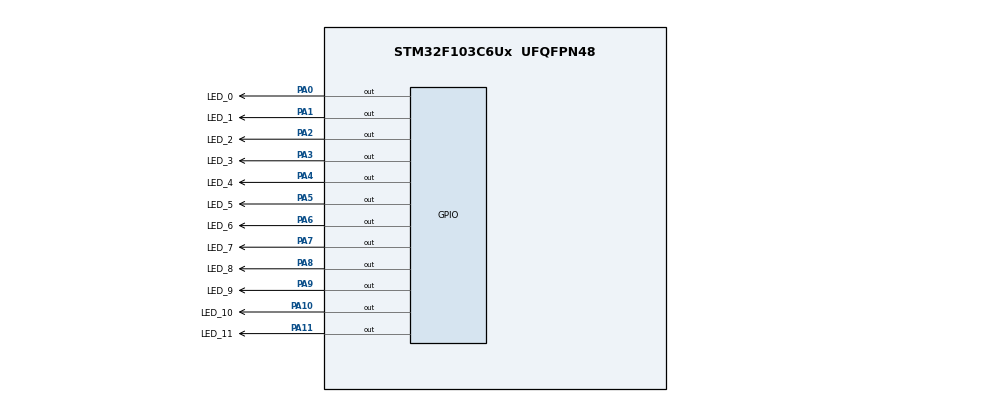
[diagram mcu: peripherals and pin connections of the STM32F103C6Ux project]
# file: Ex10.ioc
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Mcu.Family=STM32F1
Mcu.Name=STM32F103C6Ux
Mcu.Package=UFQFPN48
NVIC.PriorityGroup=NVIC_PRIORITYGROUP_4
PA0-WKUP.GPIO_Label=LED_0
PA0-WKUP.Signal=GPIO_Output
PA1.GPIO_Label=LED_1
PA1.Signal=GPIO_Output
PA10.GPIO_Label=LED_10
PA10.Signal=GPIO_Output
PA11.GPIO_Label=LED_11
PA11.Signal=GPIO_Output
PA2.GPIO_Label=LED_2
PA2.Signal=GPIO_Output
PA3.GPIO_Label=LED_3
PA3.Signal=GPIO_Output
PA4.GPIO_Label=LED_4
PA4.Signal=GPIO_Output
PA5.GPIO_Label=LED_5
PA5.Signal=GPIO_Output
PA6.GPIO_Label=LED_6
PA6.Signal=GPIO_Output
PA7.GPIO_Label=LED_7
PA7.Signal=GPIO_Output
PA8.GPIO_Label=LED_8
PA8.Signal=GPIO_Output
PA9.GPIO_Label=LED_9
PA9.Signal=GPIO_Output
ProjectManager.HeapSize=0x200
ProjectManager.StackSize=0x400
ProjectManager.TargetToolchain=STM32CubeIDE
RCC.APB1Freq_Value=8000000
RCC.APB2Freq_Value=8000000
VP_SYS_VS_ND.Mode=No_Debug
board=custom

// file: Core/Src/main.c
/* USER CODE BEGIN Header */
/**
  ******************************************************************************
  * @file           : main.c
  * @brief          : Main program body
  ******************************************************************************
  * @attention
  *
  * <h2><center>&copy; Copyright (c) 2025 STMicroelectronics.
  * All rights reserved.</center></h2>
  *
  * This software component is licensed by ST under BSD 3-Clause license,
  * the "License"; You may not use this file except in compliance with the
  * License. You may obtain a copy of the License at:
  *                        opensource.org/licenses/BSD-3-Clause
  *
  ******************************************************************************
  */
/* USER CODE END Header */
#include "main.h"

/* USER CODE BEGIN PTD */
static uint16_t LED_PIN[12] = {
		LED_1_Pin,
		LED_2_Pin,
		LED_3_Pin,
		LED_4_Pin,
		LED_5_Pin,
		LED_6_Pin,
		LED_7_Pin,
		LED_8_Pin,
		LED_9_Pin,
		LED_10_Pin,
		LED_11_Pin,
		LED_0_Pin,
};
/* USER CODE END PTD */

static int hour = 10;
static int minute = 30;
static int second = 0;

void SystemClock_Config(void);
static void MX_GPIO_Init(void);

int main(void)
{

  /* MCU Configuration--------------------------------------------------------*/

  /* Reset of all peripherals, Initializes the Flash interface and the Systick. */
  HAL_Init();

  /* Configure the system clock */
  SystemClock_Config();

  /* Initialize all configured peripherals */
  MX_GPIO_Init();
  void setNumberOnClocK(int num) { //exercise 8
	  HAL_GPIO_WritePin(GPIOA, LED_PIN[num], GPIO_PIN_SET);
  }

  void clearNumberOnClock(int num) { //exercise 9
	  HAL_GPIO_WritePin(GPIOA, LED_PIN[num], GPIO_PIN_RESET);
  }

  void clearAllClock() { // exercise 7
	  for (int i = 0; i < 12; i++) {
		  clearNumberOnClock(i);
	  }
  }

  void displayTime(int hr, int mn, int sec) { // exercise 10
	  if (hr >= 12) {
		  hr -= 12;
	  }

	  if (hr == 0) {
		  hr = 12;
	  }

	  hr = hr - 1;
	  int minuteLed = (mn + 4) / 5;
	  int secondLed = (sec + 4) / 5;
	  minuteLed = (minuteLed == 0) ? 11 : minuteLed - 1;
	  secondLed = (secondLed == 0) ? 11 : secondLed - 1;

	  clearAllClock();

	  setNumberOnClocK(hr);
	  setNumberOnClocK(minuteLed);
	  setNumberOnClocK(secondLed);

  }

  /* Infinite loop */
  while (1)
  {
	  HAL_Delay(10);
	  second += 1;
	  if (second >= 60){
		  minute += 1;
		  second = 0;
		  if (minute >= 60){
			  hour += 1;
			  minute = 0;
			  if (hour > 12) {
				  hour = 1;
			  }
		  }
	  }

	  displayTime(hour, minute, second);
  }
}

void SystemClock_Config(void)
{
  RCC_OscInitTypeDef RCC_OscInitStruct = {0};
  RCC_ClkInitTypeDef RCC_ClkInitStruct = {0};

  /** Initializes the RCC Oscillators according to the specified parameters
  * in the RCC_OscInitTypeDef structure.
  */
  RCC_OscInitStruct.OscillatorType = RCC_OSCILLATORTYPE_HSI;
  RCC_OscInitStruct.HSIState = RCC_HSI_ON;
  RCC_OscInitStruct.HSICalibrationValue = RCC_HSICALIBRATION_DEFAULT;
  RCC_OscInitStruct.PLL.PLLState = RCC_PLL_NONE;
  if (HAL_RCC_OscConfig(&RCC_OscInitStruct) != HAL_OK)
  {
    Error_Handler();
  }
  /** Initializes the CPU, AHB and APB buses clocks
  */
  RCC_ClkInitStruct.ClockType = RCC_CLOCKTYPE_HCLK|RCC_CLOCKTYPE_SYSCLK
                              |RCC_CLOCKTYPE_PCLK1|RCC_CLOCKTYPE_PCLK2;
  RCC_ClkInitStruct.SYSCLKSource = RCC_SYSCLKSOURCE_HSI;
  RCC_ClkInitStruct.AHBCLKDivider = RCC_SYSCLK_DIV1;
  RCC_ClkInitStruct.APB1CLKDivider = RCC_HCLK_DIV1;
  RCC_ClkInitStruct.APB2CLKDivider = RCC_HCLK_DIV1;

  if (HAL_RCC_ClockConfig(&RCC_ClkInitStruct, FLASH_LATENCY_0) != HAL_OK)
  {
    Error_Handler();
  }
}

static void MX_GPIO_Init(void)
{
  GPIO_InitTypeDef GPIO_InitStruct = {0};

  /* GPIO Ports Clock Enable */
  __HAL_RCC_GPIOA_CLK_ENABLE();

  /*Configure GPIO pin Output Level */
  HAL_GPIO_WritePin(GPIOA, LED_0_Pin|LED_1_Pin|LED_2_Pin|LED_3_Pin
                          |LED_4_Pin|LED_5_Pin|LED_6_Pin|LED_7_Pin
                          |LED_8_Pin|LED_9_Pin|LED_10_Pin|LED_11_Pin, GPIO_PIN_RESET);

  /*Configure GPIO pins : LED_0_Pin LED_1_Pin LED_2_Pin LED_3_Pin
                           LED_4_Pin LED_5_Pin LED_6_Pin LED_7_Pin
                           LED_8_Pin LED_9_Pin LED_10_Pin LED_11_Pin */
  GPIO_InitStruct.Pin = LED_0_Pin|LED_1_Pin|LED_2_Pin|LED_3_Pin
                          |LED_4_Pin|LED_5_Pin|LED_6_Pin|LED_7_Pin
                          |LED_8_Pin|LED_9_Pin|LED_10_Pin|LED_11_Pin;
  GPIO_InitStruct.Mode = GPIO_MODE_OUTPUT_PP;
  GPIO_InitStruct.Pull = GPIO_NOPULL;
  GPIO_InitStruct.Speed = GPIO_SPEED_FREQ_LOW;
  HAL_GPIO_Init(GPIOA, &GPIO_InitStruct);

}

void Error_Handler(void)
{
  __disable_irq();
  while (1)
  {
  }
}

/************************ (C) COPYRIGHT STMicroelectronics *****END OF FILE****/
